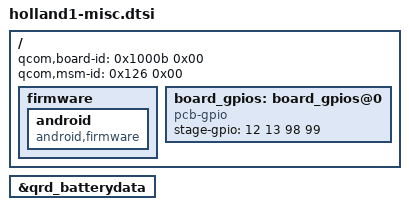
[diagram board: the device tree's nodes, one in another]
/* Copyright (c) 2020, The Linux Foundation. All rights reserved.
*  Copyright (c) 2020, Jebaitedneko.
*
* This program is free software; you can redistribute it and/or modify
* it under the terms of the GNU General Public License version 2 and
* only version 2 as published by the Free Software Foundation.
*
* This program is distributed in the hope that it will be useful,
* but WITHOUT ANY WARRANTY; without even the implied warranty of
* MERCHANTABILITY or FITNESS FOR A PARTICULAR PURPOSE.  See the
* GNU General Public License for more details.
*/

/ {

	qcom,board-id = <0x1000b 0x00>;
	qcom,msm-id = <0x126 0x00>;

	firmware {

		android {

			compatible = "android,firmware";

			/delete-node/ fstab;

			/delete-node/ vbmeta;

		};
	};

	board_gpios: board_gpios@0 {

		compatible = "pcb-gpio";
		stage-gpio = <12 13 98 99>;
	};
};

&qrd_batterydata {
	#include "batterydata_Amazon_4V4_4000mAh.dtsi"
	/delete-node/ qcom,qrd_msm8937_sku2_2590mah;
};
